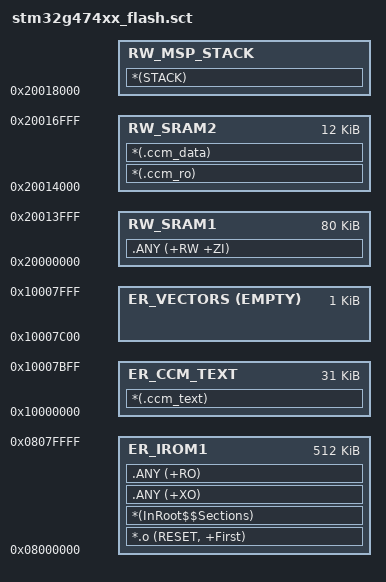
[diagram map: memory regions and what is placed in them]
LR_IROM1 0x8000000 0x00080000  {  ; load_region size_region
  ER_IROM1 0x8000000 0x00080000  {  ; load address = excetion address
   *.o (RESET, +First)
   *(InRoot$$Sections)
   .ANY (+XO)
   .ANY (+RO)
  }
;***region***;
;***endregion***;
  
  ; 高频执行的程序放在CCM SRAM(31KB)
  ER_CCM_TEXT 0x10000000 0x00007C00  {
    *(.ccm_text)
  }
  ; 中断向量表1KB也放在CCM SRAM
  ER_VECTORS 0x10007C00 EMPTY 0x00000400 {
  }

  ; 其他变量放在SRAM1(80KB)
  RW_SRAM1 0x20000000 0x00014000  {
    .ANY (+RW +ZI)
  }
  ; CCM变量和常量池放在SRAM2(12KB)
  RW_SRAM2 0x20014000 0x0003000  {
    *(.ccm_ro)
    *(.ccm_data)     
  }
  ; 堆栈4KB，从SRAM2顶部向下生长
  RW_MSP_STACK 0x20018000 -0x00001000 {
    *(STACK)
  }
  
  ; 通过填充FLASH空区域确定最大容量，发现手上这颗RBT6至少有512KB FLASH
  ; END_OF_BLOCK (0x08080000) FIXED EMPTY 0x0{}
}


/*-Start of  regions- Auto-generated By STM32CubeMX-*/
